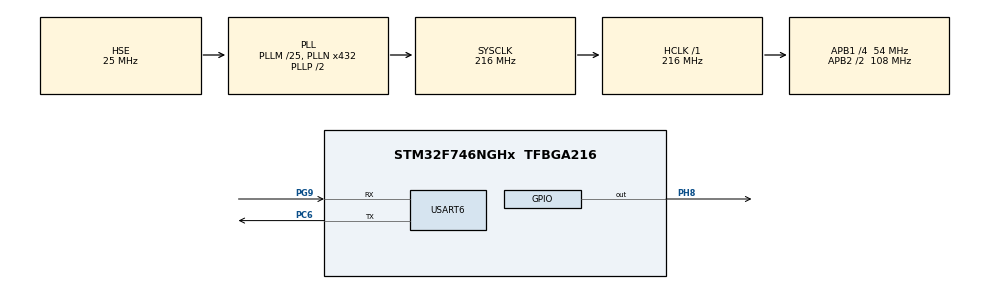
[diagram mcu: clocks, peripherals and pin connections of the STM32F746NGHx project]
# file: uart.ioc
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Mcu.Family=STM32F7
Mcu.Name=STM32F746NGHx
Mcu.Package=TFBGA216
NVIC.PriorityGroup=NVIC_PRIORITYGROUP_4
PC6.Mode=Asynchronous
PC6.Signal=USART6_TX
PG9.Mode=Asynchronous
PG9.Signal=USART6_RX
PH0/OSC_IN.Mode=HSE-External-Oscillator
PH0/OSC_IN.Signal=RCC_OSC_IN
PH1/OSC_OUT.Mode=HSE-External-Oscillator
PH1/OSC_OUT.Signal=RCC_OSC_OUT
PH8.Signal=GPIO_Output
ProjectManager.HeapSize=0x200
ProjectManager.StackSize=0x400
ProjectManager.TargetToolchain=STM32CubeIDE
RCC.AHBFreq_Value=216000000
RCC.APB1CLKDivider=RCC_HCLK_DIV4
RCC.APB1Freq_Value=54000000
RCC.APB1TimFreq_Value=108000000
RCC.APB2CLKDivider=RCC_HCLK_DIV2
RCC.APB2Freq_Value=108000000
RCC.APB2TimFreq_Value=216000000
RCC.CortexFreq_Value=216000000
RCC.HCLKFreq_Value=216000000
RCC.HSE_VALUE=25000000
RCC.HSI_VALUE=16000000
RCC.LSE_VALUE=32768
RCC.PLLM=25
RCC.PLLN=432
RCC.PLLSourceVirtual=RCC_PLLSOURCE_HSE
RCC.SYSCLKFreq_VALUE=216000000
RCC.SYSCLKSource=RCC_SYSCLKSOURCE_PLLCLK
RCC.USBFreq_Value=216000000
RCC.VCOOutputFreq_Value=432000000
USART6.VirtualMode-Asynchronous=VM_ASYNC
board=STM32F746G-DISCO

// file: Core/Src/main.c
/* USER CODE BEGIN Header */
/**
  ******************************************************************************
  * @file           : main.c
  * @brief          : Main program body
  ******************************************************************************
  * @attention
  *
  * Copyright (c) 2025 STMicroelectronics.
  * All rights reserved.
  *
  * This software is licensed under terms that can be found in the LICENSE file
  * in the root directory of this software component.
  * If no LICENSE file comes with this software, it is provided AS-IS.
  *
  ******************************************************************************
  */
/* USER CODE END Header */
#include "main.h"
//Minicom used for display of messages
//sudo minicom -b 115200 -D /dev/ttyACM0  => code to open minicom in linux with desired specifications already set intially when minicom was installed

/* USER CODE BEGIN Includes */
#include <string.h>
/* USER CODE END Includes */

UART_HandleTypeDef huart6;

void SystemClock_Config(void);
static void MX_GPIO_Init(void);
static void MX_USART6_UART_Init(void);

int main(void)
{

  /* MCU Configuration--------------------------------------------------------*/

  /* Reset of all peripherals, Initializes the Flash interface and the Systick. */
  HAL_Init();

  /* Configure the system clock */
  SystemClock_Config();

  /* Initialize all configured peripherals */
  MX_GPIO_Init();
  MX_USART6_UART_Init();
  /* USER CODE BEGIN 2 */
  char msg[] = "Hello from STM32F746 over USART6!\r\n";
  uint8_t rx_data[100];
  /* USER CODE END 2 */

  /* Infinite loop */
  /* USER CODE BEGIN WHILE */
  while (1)
  {
	  HAL_GPIO_WritePin(GPIOH, GPIO_PIN_8, GPIO_PIN_RESET);
	  HAL_Delay(1000);
	  HAL_GPIO_WritePin(GPIOH, GPIO_PIN_8, GPIO_PIN_SET);
	  HAL_Delay(1000);
	  //Transmit from MCU to PC
	  HAL_UART_Transmit(&huart6, (uint8_t*)msg, strlen(msg), HAL_MAX_DELAY);
	  HAL_Delay(1000);

	  //Transmit character from pc to MCU
	  if(HAL_UART_Receive(&huart6, rx_data, 1, 100) == HAL_OK)
	  {
		  //This will append character to rx_data
		  HAL_UART_Transmit(&huart6, rx_data, 1, 100);
	  }
    /* USER CODE END WHILE */

  }
}

void SystemClock_Config(void)
{
  RCC_OscInitTypeDef RCC_OscInitStruct = {0};
  RCC_ClkInitTypeDef RCC_ClkInitStruct = {0};

  /** Configure the main internal regulator output voltage
  */
  __HAL_RCC_PWR_CLK_ENABLE();
  __HAL_PWR_VOLTAGESCALING_CONFIG(PWR_REGULATOR_VOLTAGE_SCALE1);

  /** Initializes the RCC Oscillators according to the specified parameters
  * in the RCC_OscInitTypeDef structure.
  */
  RCC_OscInitStruct.OscillatorType = RCC_OSCILLATORTYPE_HSE;
  RCC_OscInitStruct.HSEState = RCC_HSE_ON;
  RCC_OscInitStruct.PLL.PLLState = RCC_PLL_ON;
  RCC_OscInitStruct.PLL.PLLSource = RCC_PLLSOURCE_HSE;
  RCC_OscInitStruct.PLL.PLLM = 25;
  RCC_OscInitStruct.PLL.PLLN = 432;
  RCC_OscInitStruct.PLL.PLLP = RCC_PLLP_DIV2;
  RCC_OscInitStruct.PLL.PLLQ = 2;
  if (HAL_RCC_OscConfig(&RCC_OscInitStruct) != HAL_OK)
  {
    Error_Handler();
  }

  /** Activate the Over-Drive mode
  */
  if (HAL_PWREx_EnableOverDrive() != HAL_OK)
  {
    Error_Handler();
  }

  /** Initializes the CPU, AHB and APB buses clocks
  */
  RCC_ClkInitStruct.ClockType = RCC_CLOCKTYPE_HCLK|RCC_CLOCKTYPE_SYSCLK
                              |RCC_CLOCKTYPE_PCLK1|RCC_CLOCKTYPE_PCLK2;
  RCC_ClkInitStruct.SYSCLKSource = RCC_SYSCLKSOURCE_PLLCLK;
  RCC_ClkInitStruct.AHBCLKDivider = RCC_SYSCLK_DIV1;
  RCC_ClkInitStruct.APB1CLKDivider = RCC_HCLK_DIV4;
  RCC_ClkInitStruct.APB2CLKDivider = RCC_HCLK_DIV2;

  if (HAL_RCC_ClockConfig(&RCC_ClkInitStruct, FLASH_LATENCY_7) != HAL_OK)
  {
    Error_Handler();
  }
}

static void MX_USART6_UART_Init(void)
{

  huart6.Instance = USART6;
  huart6.Init.BaudRate = 115200;
  huart6.Init.WordLength = UART_WORDLENGTH_8B;
  huart6.Init.StopBits = UART_STOPBITS_1;
  huart6.Init.Parity = UART_PARITY_NONE;
  huart6.Init.Mode = UART_MODE_TX_RX;
  huart6.Init.HwFlowCtl = UART_HWCONTROL_NONE;
  huart6.Init.OverSampling = UART_OVERSAMPLING_16;
  huart6.Init.OneBitSampling = UART_ONE_BIT_SAMPLE_DISABLE;
  huart6.AdvancedInit.AdvFeatureInit = UART_ADVFEATURE_NO_INIT;
  if (HAL_UART_Init(&huart6) != HAL_OK)
  {
    Error_Handler();
  }

}

static void MX_GPIO_Init(void)
{
  GPIO_InitTypeDef GPIO_InitStruct = {0};

  /* GPIO Ports Clock Enable */
  __HAL_RCC_GPIOG_CLK_ENABLE();
  __HAL_RCC_GPIOH_CLK_ENABLE();
  __HAL_RCC_GPIOC_CLK_ENABLE();

  /*Configure GPIO pin Output Level */
  HAL_GPIO_WritePin(GPIOH, GPIO_PIN_8, GPIO_PIN_RESET);

  /*Configure GPIO pin : PH8 */
  GPIO_InitStruct.Pin = GPIO_PIN_8;
  GPIO_InitStruct.Mode = GPIO_MODE_OUTPUT_PP;
  GPIO_InitStruct.Pull = GPIO_NOPULL;
  GPIO_InitStruct.Speed = GPIO_SPEED_FREQ_LOW;
  HAL_GPIO_Init(GPIOH, &GPIO_InitStruct);

}

void Error_Handler(void)
{
  __disable_irq();
  while (1)
  {
  }
}
